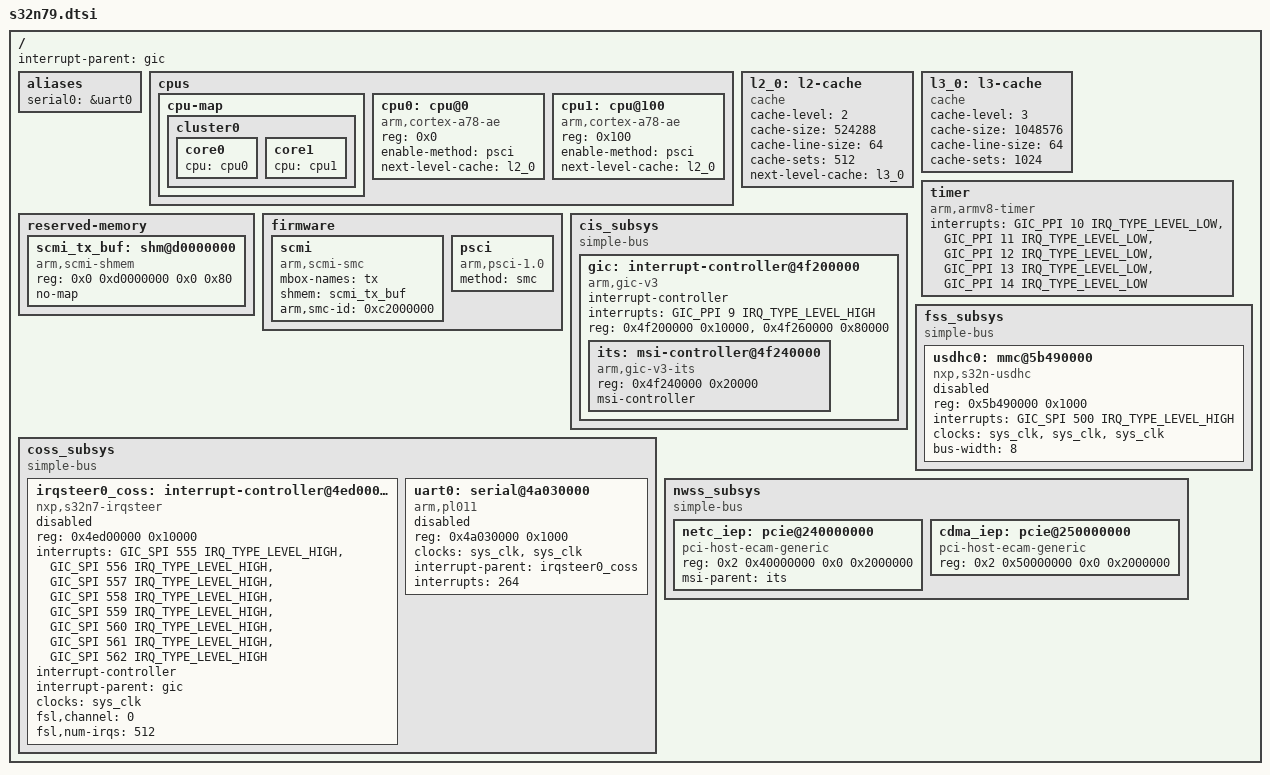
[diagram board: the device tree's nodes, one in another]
// SPDX-License-Identifier: (GPL-2.0+ OR BSD-3-Clause)
/*
 * Device Tree Include file for NXP S32N79 SoC.
 *
 * Copyright 2024 NXP
 */

#include <dt-bindings/interrupt-controller/arm-gic.h>

/ {
	interrupt-parent = <&gic>;
	#address-cells = <2>;
	#size-cells = <2>;

	aliases {
		serial0 = &uart0;
	};

	cpus {
		#address-cells = <1>;
		#size-cells = <0>;

		cpu-map {
			cluster0 {
				core0 {
					cpu = <&cpu0>;
				};

				core1 {
					cpu = <&cpu1>;
				};
			};
		};

		cpu0: cpu@0 {
			device_type = "cpu";
			compatible = "arm,cortex-a78-ae";
			reg = <0x0>;
			enable-method = "psci";
			next-level-cache = <&l2_0>;
		};

		cpu1: cpu@100 {
			device_type = "cpu";
			compatible = "arm,cortex-a78-ae";
			reg = <0x100>;
			enable-method = "psci";
			next-level-cache = <&l2_0>;
		};

	};

	l2_0: l2-cache {
		compatible = "cache";
		cache-level = <2>;
		cache-size = <524288>;
		cache-line-size = <64>;
		cache-sets = <512>;
		next-level-cache = <&l3_0>;
	};

	l3_0: l3-cache {
		compatible = "cache";
		cache-level = <3>;
		cache-size = <1048576>;
		cache-line-size = <64>;
		cache-sets = <1024>;
	};

	timer: timer {
		compatible = "arm,armv8-timer";
		interrupts = <GIC_PPI 10 IRQ_TYPE_LEVEL_LOW>,
			     <GIC_PPI 11 IRQ_TYPE_LEVEL_LOW>,
			     <GIC_PPI 12 IRQ_TYPE_LEVEL_LOW>,
			     <GIC_PPI 13 IRQ_TYPE_LEVEL_LOW>,
			     <GIC_PPI 14 IRQ_TYPE_LEVEL_LOW>;
		interrupt-names = "hyp-phys", "virt", "hyp-virt", "sec-phys", "phys";
	};

	reserved-memory  {
		#address-cells = <2>;
		#size-cells = <2>;
		ranges;

		scmi_tx_buf: shm@d0000000 {
			compatible = "arm,scmi-shmem";
			reg = <0x0 0xd0000000 0x0 0x80>;
			no-map;
		};
	};

	firmware {
		scmi: scmi {
			compatible = "arm,scmi-smc";
			mbox-names = "tx";
			shmem = <&scmi_tx_buf>;
			arm,smc-id = <0xc2000000>;
			status = "okay";
		};

		psci {
			compatible = "arm,psci-1.0";
			method = "smc";
		};
	};

	cis_subsys {
		compatible = "simple-bus";
		#address-cells = <1>;
		#size-cells = <1>;
		ranges = <0x0 0x0 0x0 0x20000000>,
			 <0x4f200000 0x0 0x4f200000 0xc00000>;

		gic: interrupt-controller@4f200000 {
			compatible = "arm,gic-v3";
			#address-cells = <1>;
			#size-cells = <1>;
			#interrupt-cells = <3>;
			interrupt-controller;
			interrupts = <GIC_PPI 9 IRQ_TYPE_LEVEL_HIGH>;
			reg = <0x4f200000 0x10000>, /* GIC Dist */
			      <0x4f260000 0x80000>; /* GICR (RD_base + SGI_base) */
			ranges;

			its: msi-controller@4f240000 {
				compatible = "arm,gic-v3-its";
				reg = <0x4f240000 0x20000>;
				msi-controller;
			};
		};

	};

	coss_subsys {
		compatible = "simple-bus";
		#address-cells = <1>;
		#size-cells = <1>;
		ranges = <0x4a000000 0x0 0x4a000000 0xff0000>,
			 <0x4e000000 0x0 0x4e000000 0x1000000>;

		irqsteer0_coss: interrupt-controller@4ed00000 {
			compatible = "nxp,s32n7-irqsteer";
			reg = <0x4ed00000 0x10000>;
			interrupts = <GIC_SPI 555 IRQ_TYPE_LEVEL_HIGH>,
				     <GIC_SPI 556 IRQ_TYPE_LEVEL_HIGH>,
				     <GIC_SPI 557 IRQ_TYPE_LEVEL_HIGH>,
				     <GIC_SPI 558 IRQ_TYPE_LEVEL_HIGH>,
				     <GIC_SPI 559 IRQ_TYPE_LEVEL_HIGH>,
				     <GIC_SPI 560 IRQ_TYPE_LEVEL_HIGH>,
				     <GIC_SPI 561 IRQ_TYPE_LEVEL_HIGH>,
				     <GIC_SPI 562 IRQ_TYPE_LEVEL_HIGH>;
			interrupt-controller;
			interrupt-parent = <&gic>;
			#interrupt-cells = <1>;
			clocks = <&sys_clk>;
			clock-names = "ipg";
			fsl,channel = <0>;
			fsl,num-irqs = <512>;
			status = "disabled";
		};

		uart0: serial@4a030000 {
			compatible = "arm,pl011", "arm,primecell";
			reg = <0x4a030000 0x1000>;
			clocks = <&sys_clk>, <&sys_clk>;
			clock-names = "uartclk", "apb_pclk";
			interrupt-parent = <&irqsteer0_coss>;
			interrupts = <264>;
			status = "disabled";
		};
	};

	fss_subsys {
		compatible = "simple-bus";
		#address-cells = <1>;
		#size-cells = <1>;
		ranges = <0x5b490000 0x0 0x5b490000 0x1000>;

		usdhc0: mmc@5b490000 {
			compatible = "nxp,s32n-usdhc";
			reg = <0x5b490000 0x1000>;
			interrupts = <GIC_SPI 500 IRQ_TYPE_LEVEL_HIGH>;
			clocks = <&sys_clk>, <&sys_clk>, <&sys_clk>;
			clock-names = "ipg", "ahb", "per";
			bus-width = <8>;
			status = "disabled";
		};
	};

	nwss_subsys {
		compatible = "simple-bus";
		#address-cells = <2>;
		#size-cells = <2>;
		ranges = <0x2 0x40000000 0x2 0x40000000 0x0 0x40000000>,
			 <0x0 0x48800000 0x0 0x48800000 0x0 0x540000>;

		netc_iep: pcie@240000000 {
			compatible = "pci-host-ecam-generic";
			reg = <0x2 0x40000000 0x0 0x2000000>;
			#address-cells = <3>;
			#size-cells = <2>;
			msi-parent = <&its>;
			device_type = "pci";

			ranges = <0x82000000 0x0 0x48800000 0x0 0x48800000 0x0 0x540000>;
		};

		cdma_iep: pcie@250000000 {
			compatible = "pci-host-ecam-generic";
			reg = <0x2 0x50000000 0x0 0x2000000>;
			#address-cells = <3>;
			#size-cells = <2>;
			device_type = "pci";

			ranges = <0x82000000 0x0 0x47c00000 0x0 0x47c00000 0x0 0x620000>;
		};
	};
};
